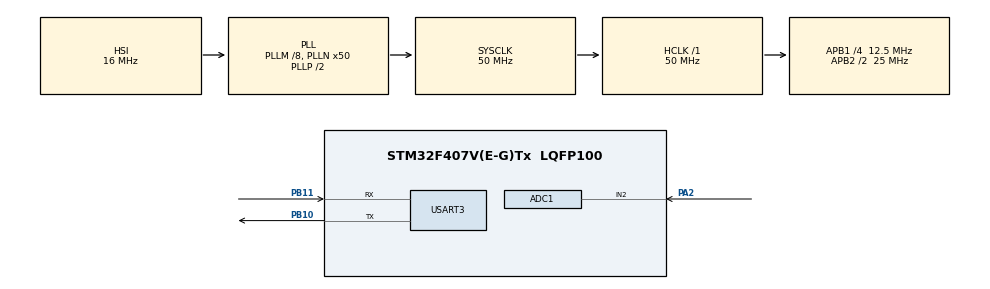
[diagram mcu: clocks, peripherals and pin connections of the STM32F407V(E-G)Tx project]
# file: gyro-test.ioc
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ADC1.Channel-1\#ChannelRegularConversion=ADC_CHANNEL_2
ADC1.NbrOfConversionFlag=1
ADC1.Rank-1\#ChannelRegularConversion=1
ADC1.SamplingTime-1\#ChannelRegularConversion=ADC_SAMPLETIME_3CYCLES
ADC1.master=1
Mcu.Family=STM32F4
Mcu.Name=STM32F407V(E-G)Tx
Mcu.Package=LQFP100
NVIC.PriorityGroup=NVIC_PRIORITYGROUP_0
NVIC.USART3_IRQn=true\:0\:0\:false\:false\:true\:true\:true
PA2.Signal=ADCx_IN2
PB10.Mode=Asynchronous
PB10.Signal=USART3_TX
PB11.Mode=Asynchronous
PB11.Signal=USART3_RX
ProjectManager.HeapSize=0x2000
ProjectManager.StackSize=0x4000
ProjectManager.TargetToolchain=SW4STM32
RCC.48MHZClocksFreq_Value=14285714.285714285
RCC.AHBFreq_Value=50000000
RCC.APB1CLKDivider=RCC_HCLK_DIV4
RCC.APB1Freq_Value=12500000
RCC.APB1TimFreq_Value=25000000
RCC.APB2CLKDivider=RCC_HCLK_DIV2
RCC.APB2Freq_Value=25000000
RCC.APB2TimFreq_Value=50000000
RCC.CortexFreq_Value=50000000
RCC.HCLKFreq_Value=50000000
RCC.HSE_VALUE=8000000
RCC.HSI_VALUE=16000000
RCC.LSE_VALUE=32768
RCC.PLLM=8
RCC.PLLN=50
RCC.PLLQ=7
RCC.SYSCLKFreq_VALUE=50000000
RCC.SYSCLKSource=RCC_SYSCLKSOURCE_PLLCLK
RCC.VCOOutputFreq_Value=100000000
SH.ADCx_IN2.0=ADC1_IN2,IN2
USART3.VirtualMode=VM_ASYNC
board=STM32F4DISCOVERY

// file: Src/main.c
#include "main.h"
#include <stdio.h>
#include "STLISY300AL.h"

ADC_HandleTypeDef hadc1;

UART_HandleTypeDef huart3;

Lisy300al gyro;

void SystemClock_Config(void);
static void MX_GPIO_Init(void);
static void MX_USART3_UART_Init(void);
static void MX_ADC1_Init(void);

#define GYRO_SENSETIVITY   0.0033
#define ANALOG_SENSETIVITY 0.0008

int main(void)
{

  /* MCU Configuration--------------------------------------------------------*/

  /* Reset of all peripherals, Initializes the Flash interface and the Systick. */
  HAL_Init();

  /* Configure the system clock */
  SystemClock_Config();

  /* Initialize all configured peripherals */
  MX_GPIO_Init();
  MX_USART3_UART_Init();
  MX_ADC1_Init();
  Init_Lisy300al(&gyro, &hadc1);

  /* Infinite loop */
  /* USER CODE BEGIN WHILE */

  uint8_t data[100] = {};

  uint32_t zero_pos = 0;
  uint64_t lasttook = 0;
  uint64_t timetook = 0;
  float angle       = 0;

  for (uint8_t iter = 0; iter < 10; ++iter) {
	  HAL_ADC_Start(&hadc1);
	  HAL_ADC_PollForConversion(&hadc1, 100);
	  zero_pos += HAL_ADC_GetValue(&hadc1);
	  HAL_ADC_Stop(&hadc1);
	  HAL_Delay(10);
  }

  zero_pos /= 10;

  while (1)
  {
	  HAL_ADC_Start(&hadc1);
	  HAL_ADC_PollForConversion(&hadc1, 100);
	  uint16_t gyro_x = HAL_ADC_GetValue(&hadc1);
	  HAL_ADC_Stop(&hadc1);

	  int16_t change = 0;

	  if (fabs(gyro_x - zero_pos) > 200)
		  change = gyro_x - zero_pos;

	  lasttook = timetook;
	  timetook = HAL_GetTick();

	  float time = ( (float)(timetook) - (float)(lasttook) ) / 1000.0f;

	  float degchange = change * time * ANALOG_SENSETIVITY / GYRO_SENSETIVITY;

	  angle += degchange;

	  if (angle > 360) angle -= 360;
	  if (angle < 0)   angle += 360;

	  sprintf(data, "value = %1.5f \r\n", angle);

	  HAL_UART_Transmit(&huart3, data, 100, 0xFFFF);

	  HAL_Delay(100);

//	  float value = get_position(&gyro, &hadc1);
//
//	  sprintf(data, "%d \r\n", (int)(value));
//
//	  HAL_UART_Transmit(&huart3, data, 100, 0xFFFF);
//
//	  HAL_Delay(10);

    /* USER CODE END WHILE */

  }
}

void SystemClock_Config(void)
{
  RCC_OscInitTypeDef RCC_OscInitStruct = {0};
  RCC_ClkInitTypeDef RCC_ClkInitStruct = {0};

  /** Configure the main internal regulator output voltage
  */
  __HAL_RCC_PWR_CLK_ENABLE();
  __HAL_PWR_VOLTAGESCALING_CONFIG(PWR_REGULATOR_VOLTAGE_SCALE1);
  /** Initializes the CPU, AHB and APB busses clocks
  */
  RCC_OscInitStruct.OscillatorType = RCC_OSCILLATORTYPE_HSI;
  RCC_OscInitStruct.HSIState = RCC_HSI_ON;
  RCC_OscInitStruct.HSICalibrationValue = RCC_HSICALIBRATION_DEFAULT;
  RCC_OscInitStruct.PLL.PLLState = RCC_PLL_ON;
  RCC_OscInitStruct.PLL.PLLSource = RCC_PLLSOURCE_HSI;
  RCC_OscInitStruct.PLL.PLLM = 8;
  RCC_OscInitStruct.PLL.PLLN = 50;
  RCC_OscInitStruct.PLL.PLLP = RCC_PLLP_DIV2;
  RCC_OscInitStruct.PLL.PLLQ = 7;
  if (HAL_RCC_OscConfig(&RCC_OscInitStruct) != HAL_OK)
  {
    Error_Handler();
  }
  /** Initializes the CPU, AHB and APB busses clocks
  */
  RCC_ClkInitStruct.ClockType = RCC_CLOCKTYPE_HCLK|RCC_CLOCKTYPE_SYSCLK
                              |RCC_CLOCKTYPE_PCLK1|RCC_CLOCKTYPE_PCLK2;
  RCC_ClkInitStruct.SYSCLKSource = RCC_SYSCLKSOURCE_PLLCLK;
  RCC_ClkInitStruct.AHBCLKDivider = RCC_SYSCLK_DIV1;
  RCC_ClkInitStruct.APB1CLKDivider = RCC_HCLK_DIV4;
  RCC_ClkInitStruct.APB2CLKDivider = RCC_HCLK_DIV2;

  if (HAL_RCC_ClockConfig(&RCC_ClkInitStruct, FLASH_LATENCY_1) != HAL_OK)
  {
    Error_Handler();
  }
}

static void MX_ADC1_Init(void)
{

  ADC_ChannelConfTypeDef sConfig = {0};

  /** Configure the global features of the ADC (Clock, Resolution, Data Alignment and number of conversion)
  */
  hadc1.Instance = ADC1;
  hadc1.Init.ClockPrescaler = ADC_CLOCK_SYNC_PCLK_DIV2;
  hadc1.Init.Resolution = ADC_RESOLUTION_12B;
  hadc1.Init.ScanConvMode = DISABLE;
  hadc1.Init.ContinuousConvMode = DISABLE;
  hadc1.Init.DiscontinuousConvMode = DISABLE;
  hadc1.Init.ExternalTrigConvEdge = ADC_EXTERNALTRIGCONVEDGE_NONE;
  hadc1.Init.ExternalTrigConv = ADC_SOFTWARE_START;
  hadc1.Init.DataAlign = ADC_DATAALIGN_RIGHT;
  hadc1.Init.NbrOfConversion = 1;
  hadc1.Init.DMAContinuousRequests = DISABLE;
  hadc1.Init.EOCSelection = ADC_EOC_SINGLE_CONV;
  if (HAL_ADC_Init(&hadc1) != HAL_OK)
  {
    Error_Handler();
  }
  /** Configure for the selected ADC regular channel its corresponding rank in the sequencer and its sample time.
  */
  sConfig.Channel = ADC_CHANNEL_2;
  sConfig.Rank = 1;
  sConfig.SamplingTime = ADC_SAMPLETIME_3CYCLES;
  if (HAL_ADC_ConfigChannel(&hadc1, &sConfig) != HAL_OK)
  {
    Error_Handler();
  }

}

static void MX_USART3_UART_Init(void)
{

  huart3.Instance = USART3;
  huart3.Init.BaudRate = 115200;
  huart3.Init.WordLength = UART_WORDLENGTH_8B;
  huart3.Init.StopBits = UART_STOPBITS_1;
  huart3.Init.Parity = UART_PARITY_NONE;
  huart3.Init.Mode = UART_MODE_TX_RX;
  huart3.Init.HwFlowCtl = UART_HWCONTROL_NONE;
  huart3.Init.OverSampling = UART_OVERSAMPLING_16;
  if (HAL_UART_Init(&huart3) != HAL_OK)
  {
    Error_Handler();
  }

}

static void MX_GPIO_Init(void)
{

  /* GPIO Ports Clock Enable */
  __HAL_RCC_GPIOA_CLK_ENABLE();
  __HAL_RCC_GPIOB_CLK_ENABLE();

}

void Error_Handler(void)
{
}

/************************ (C) COPYRIGHT STMicroelectronics *****END OF FILE****/
